# STM32WLE5_CM4 register map
File version: 1.4
CPU: CM4 r0p1, little endian, MPU, FPU, 4 interrupt priority bits
Registers are 32-bit, read-write, reset 0x0 unless marked. A register's access mark holds for its fields unless they carry their own. Offsets are from the block's base; [hi:lo] are bit positions; {n}, {i} and the like mark numbered series.

## SCB_ACTRL — System control block ACTLR
Base 0xE000E008
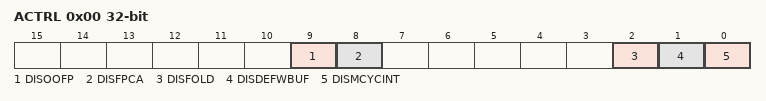
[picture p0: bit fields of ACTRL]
0x00 ACTRL — Auxiliary control register
  [9] DISOOFP, [8] DISFPCA, [2] DISFOLD, [1] DISDEFWBUF, [0] DISMCYCINT

## SPI1 — Serial peripheral interface/Inter-IC sound
Base 0x40013000
Same registers: SPI2 0x40003800, SPI3 0x58010000
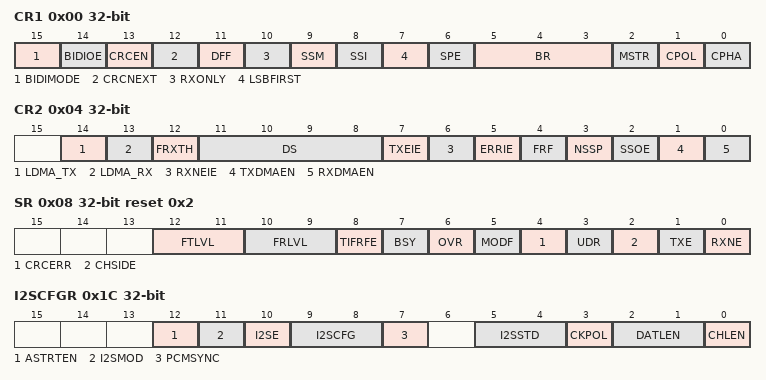
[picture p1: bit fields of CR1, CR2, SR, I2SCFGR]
0x00 CR1 — control register 1
  [15] BIDIMODE — Bidirectional data mode enable
  [14] BIDIOE — Output enable in bidirectional mode
  [13] CRCEN — Hardware CRC calculation enable
  [12] CRCNEXT — CRC transfer next
  [11] DFF — Data frame format
  [10] RXONLY — Receive only
  [9] SSM — Software slave management
  [8] SSI — Internal slave select
  [7] LSBFIRST — Frame format
  [6] SPE — SPI enable
  [5:3] BR — Baud rate control
  [2] MSTR — Master selection
  [1] CPOL — Clock polarity
  [0] CPHA — Clock phase
0x04 CR2 — control register 2
  [14] LDMA_TX — Last DMA transfer for transmission
  [13] LDMA_RX — Last DMA transfer for reception
  [12] FRXTH — FIFO reception threshold
  [11:8] DS — Data size
  [7] TXEIE — Tx buffer empty interrupt enable
  [6] RXNEIE — RX buffer not empty interrupt enable
  [5] ERRIE — Error interrupt enable
  [4] FRF — Frame format
  [3] NSSP — NSS pulse management
  [2] SSOE — SS output enable
  [1] TXDMAEN — Tx buffer DMA enable
  [0] RXDMAEN — Rx buffer DMA enable
0x08 SR access per field reset 0x2 — status register
  [12:11] FTLVL ro — FIFO transmission level
  [10:9] FRLVL ro — FIFO reception level
  [8] TIFRFE ro — TI frame format error
  [7] BSY ro — Busy flag
  [6] OVR ro — Overrun flag
  [5] MODF ro — Mode fault
  [4] CRCERR rw — CRC error flag
  [3] UDR ro
  [2] CHSIDE ro
  [1] TXE ro — Transmit buffer empty
  [0] RXNE ro — Receive buffer not empty
0x0C DR — data register
  [15:0] DR — Data register
0x10 CRCPR reset 0x7 — CRC polynomial register
  [15:0] CRCPOLY
0x14 RXCRCR ro — RX CRC register
  [15:0] RxCRC
0x18 TXCRCR ro — TX CRC register
  [15:0] TxCRC
0x1C I2SCFGR — configuration register
  [12] ASTRTEN, [11] I2SMOD, [10] I2SE, [9:8] I2SCFG, [7] PCMSYNC, [5:4] I2SSTD, [3] CKPOL, [2:1] DATLEN, [0] CHLEN
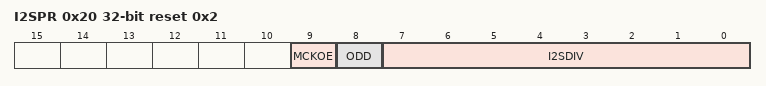
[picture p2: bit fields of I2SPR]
0x20 I2SPR reset 0x2 — prescaler register
  [9] MCKOE, [8] ODD, [7:0] I2SDIV

## STK — SysTick timer
Base 0xE000E010
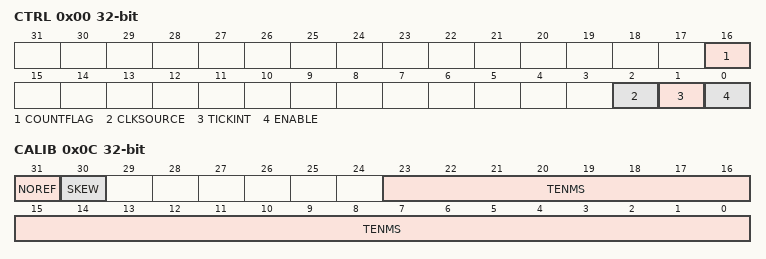
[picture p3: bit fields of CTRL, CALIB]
0x00 CTRL — SysTick control and status register
  [16] COUNTFLAG
  [2] CLKSOURCE — Clock source selection
  [1] TICKINT — SysTick exception request enable
  [0] ENABLE — Counter enable
0x04 LOAD — SysTick reload value register
  [23:0] RELOAD — RELOAD value
0x08 VAL — SysTick current value register
  [23:0] CURRENT — Current counter value
0x0C CALIB — SysTick calibration value register
  [31] NOREF — NOREF flag. Reads as zero
  [30] SKEW — SKEW flag: Indicates whether the TENMS value is exact
  [23:0] TENMS — Calibration value

## SYSCFG — System configuration controller
Base 0x40010000
0x00 MEMRMP — memory remap register
  [2:0] MEM_MODE — Memory mapping selection
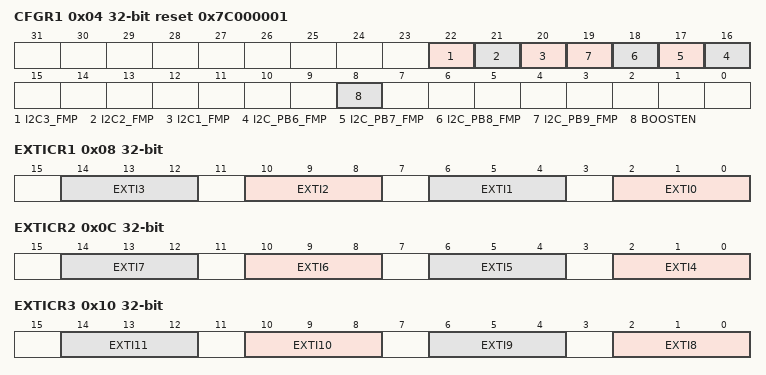
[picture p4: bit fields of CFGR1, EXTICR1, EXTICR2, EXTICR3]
0x04 CFGR1 reset 0x7C000001 — configuration register 1
  [22] I2C3_FMP — I2C3 Fast-mode Plus driving capability activation
  [21] I2C2_FMP — I2C2 Fast-mode Plus driving capability activation
  [20] I2C1_FMP — I2C1 Fast-mode Plus driving capability activation
  [n+10] I2C_PB{n}_FMP (n=6..9) — Fast-mode Plus (Fm+) driving capability activation on PB{n}
  [8] BOOSTEN — I/O analog switch voltage booster enable
0x08 EXTICR1 — external interrupt configuration register 1
  [4n+2:4n] EXTI{n} (n=0..3) — EXTI {n} configuration bits
0x0C EXTICR2 — external interrupt configuration register 2
  [4n-14:4n-16] EXTI{n} (n=4..7) — EXTI {n} configuration bits
0x10 EXTICR3 — external interrupt configuration register 3
  [4n-30:4n-32] EXTI{n} (n=8..11) — EXTI {n} configuration bits
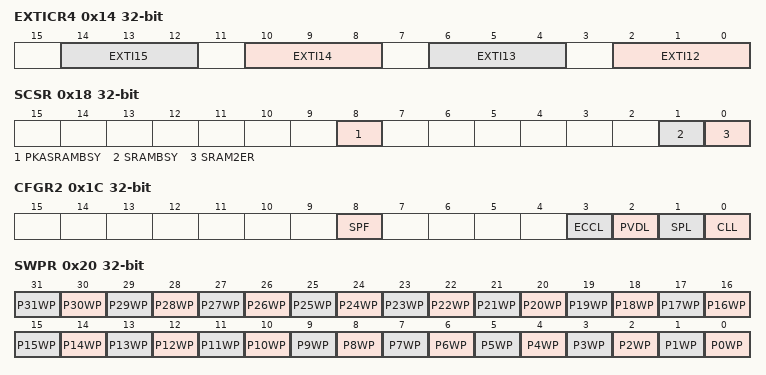
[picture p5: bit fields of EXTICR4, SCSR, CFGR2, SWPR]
0x14 EXTICR4 — external interrupt configuration register 4
  [4n-46:4n-48] EXTI{n} (n=12..15) — EXTI{n} configuration bits
0x18 SCSR access per field
  [8] PKASRAMBSY ro — PKA SRAM busy by erase operation
  [1] SRAMBSY ro — SRAM1, SRAM2 and PKA SRAM busy by erase operation
  [0] SRAM2ER rw — SRAM2 erase
0x1C CFGR2
  [8] SPF — SRAM2 parity error flag
  [3] ECCL — ECC Lock
  [2] PVDL — PVD lock enable bit
  [1] SPL — SRAM2 parity lock bit
  [0] CLL — CPU1 LOCKUP (Hardfault) output enable bit
0x20 SWPR
  [n] P{n}WP (n=0..31) — SRAM2 1Kbyte page {n} write protection
0x24 SKR wo
  [7:0] KEY — SRAM2 write protection key for software erase
0x208 RFDCR — radio debug control register
  [0] RFTBSEL — radio debug test bus selection
